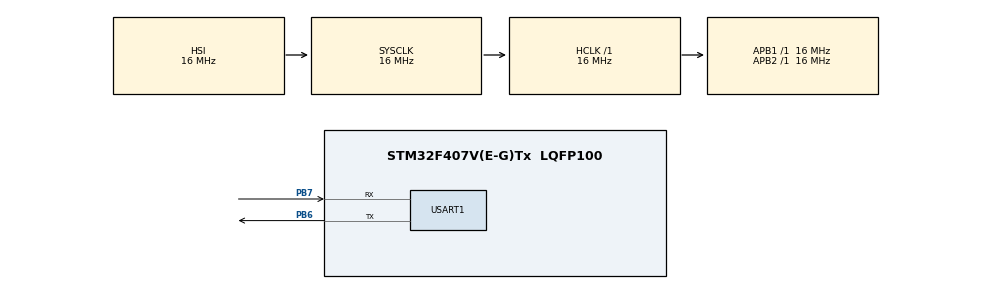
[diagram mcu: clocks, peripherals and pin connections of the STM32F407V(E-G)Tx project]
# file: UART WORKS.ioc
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Mcu.Family=STM32F4
RCC.CortexFreq_Value=16000000
Dma.USART1_RX.0.PeriphDataAlignment=DMA_PDATAALIGN_BYTE
ProjectManager.StackSize=0x400
ProjectManager.TargetToolchain=STM32CubeIDE
Dma.USART1_RX.0.Direction=DMA_PERIPH_TO_MEMORY
PB6.Signal=USART1_TX
PB6.Mode=Asynchronous
RCC.LSE_VALUE=32768
RCC.AHBFreq_Value=16000000
Dma.USART1_RX.0.PeriphInc=DMA_PINC_DISABLE
Dma.USART1_RX.0.Priority=DMA_PRIORITY_LOW
RCC.HSE_VALUE=25000000
board=custom
RCC.VCOOutputFreq_Value=192000000
RCC.APB2Freq_Value=16000000
Dma.USART1_RX.0.MemDataAlignment=DMA_MDATAALIGN_BYTE
PB7.Signal=USART1_RX
Dma.USART1_RX.0.MemInc=DMA_MINC_ENABLE
Mcu.Name=STM32F407V(E-G)Tx
RCC.SYSCLKFreq_VALUE=16000000
Mcu.Package=LQFP100
USART1.VirtualMode=VM_ASYNC
PB7.Mode=Asynchronous
ProjectManager.HeapSize=0x200
RCC.HSI_VALUE=16000000
NVIC.PriorityGroup=NVIC_PRIORITYGROUP_4
Dma.USART1_RX.0.FIFOMode=DMA_FIFOMODE_DISABLE
NVIC.DMA2_Stream2_IRQn=true\:0\:0\:false\:false\:true\:false\:true
Dma.USART1_RX.0.Mode=DMA_CIRCULAR
NVIC.USART1_IRQn=true\:0\:0\:false\:false\:true\:true\:true
Dma.Request0=USART1_RX
RCC.APB1Freq_Value=16000000
Dma.USART1_RX.0.Instance=DMA2_Stream2

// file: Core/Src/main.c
/* USER CODE BEGIN Header */
/**
  ******************************************************************************
  * @file           : main.c
  * @brief          : Main program body
  ******************************************************************************
  * @attention
  *
  * <h2><center>&copy; Copyright (c) 2021 STMicroelectronics.
  * All rights reserved.</center></h2>
  *
  * This software component is licensed by ST under BSD 3-Clause license,
  * the "License"; You may not use this file except in compliance with the
  * License. You may obtain a copy of the License at:
  *                        opensource.org/licenses/BSD-3-Clause
  *
  ******************************************************************************
  */
/* USER CODE END Header */
#include "main.h"

UART_HandleTypeDef huart1;
DMA_HandleTypeDef hdma_usart1_rx;

void SystemClock_Config(void);
static void MX_GPIO_Init(void);
static void MX_DMA_Init(void);
static void MX_USART1_UART_Init(void);

/* USER CODE BEGIN 0 */
uint8_t FirstTxData[26]= "w axis0.requested_state 3\n";
uint8_t myTxData[22]= "r axis0.current_state\n";
uint8_t myTxData1[15]= "r vbus_voltage\n";
uint8_t myRxData[1] = "0";
uint8_t in_buf[16]="0";
uint8_t n_inbuf=0;
/* USER CODE END 0 */

int main(void)
{

  /* MCU Configuration--------------------------------------------------------*/

  /* Reset of all peripherals, Initializes the Flash interface and the Systick. */
  HAL_Init();

  /* Configure the system clock */
  SystemClock_Config();

  /* Initialize all configured peripherals */
  MX_GPIO_Init();
  MX_DMA_Init();
  MX_USART1_UART_Init();
  /* USER CODE BEGIN 2 */
  HAL_UART_Receive_DMA(&huart1, myRxData, 1);
  //HAL_UART_Transmit(&huart1, FirstTxData, 26, 20);
  HAL_Delay(200);
  /* USER CODE END 2 */

  /* Infinite loop */
  while (1)
  {

    /* USER CODE BEGIN 3 */
	  HAL_UART_Transmit(&huart1, myTxData, 22, 20);
	  HAL_Delay(1000);
	  HAL_UART_Transmit(&huart1, myTxData1, 15, 20);

	  HAL_Delay(1000);
  }
  /* USER CODE END 3 */
}

void SystemClock_Config(void)
{
  RCC_OscInitTypeDef RCC_OscInitStruct = {0};
  RCC_ClkInitTypeDef RCC_ClkInitStruct = {0};

  /** Configure the main internal regulator output voltage
  */
  __HAL_RCC_PWR_CLK_ENABLE();
  __HAL_PWR_VOLTAGESCALING_CONFIG(PWR_REGULATOR_VOLTAGE_SCALE1);
  /** Initializes the RCC Oscillators according to the specified parameters
  * in the RCC_OscInitTypeDef structure.
  */
  RCC_OscInitStruct.OscillatorType = RCC_OSCILLATORTYPE_HSI;
  RCC_OscInitStruct.HSIState = RCC_HSI_ON;
  RCC_OscInitStruct.HSICalibrationValue = RCC_HSICALIBRATION_DEFAULT;
  RCC_OscInitStruct.PLL.PLLState = RCC_PLL_NONE;
  if (HAL_RCC_OscConfig(&RCC_OscInitStruct) != HAL_OK)
  {
    Error_Handler();
  }
  /** Initializes the CPU, AHB and APB buses clocks
  */
  RCC_ClkInitStruct.ClockType = RCC_CLOCKTYPE_HCLK|RCC_CLOCKTYPE_SYSCLK
                              |RCC_CLOCKTYPE_PCLK1|RCC_CLOCKTYPE_PCLK2;
  RCC_ClkInitStruct.SYSCLKSource = RCC_SYSCLKSOURCE_HSI;
  RCC_ClkInitStruct.AHBCLKDivider = RCC_SYSCLK_DIV1;
  RCC_ClkInitStruct.APB1CLKDivider = RCC_HCLK_DIV1;
  RCC_ClkInitStruct.APB2CLKDivider = RCC_HCLK_DIV1;

  if (HAL_RCC_ClockConfig(&RCC_ClkInitStruct, FLASH_LATENCY_0) != HAL_OK)
  {
    Error_Handler();
  }
}

static void MX_USART1_UART_Init(void)
{

  huart1.Instance = USART1;
  huart1.Init.BaudRate = 115200;
  huart1.Init.WordLength = UART_WORDLENGTH_8B;
  huart1.Init.StopBits = UART_STOPBITS_1;
  huart1.Init.Parity = UART_PARITY_NONE;
  huart1.Init.Mode = UART_MODE_TX_RX;
  huart1.Init.HwFlowCtl = UART_HWCONTROL_NONE;
  huart1.Init.OverSampling = UART_OVERSAMPLING_16;
  if (HAL_UART_Init(&huart1) != HAL_OK)
  {
    Error_Handler();
  }

}

static void MX_DMA_Init(void)
{

  /* DMA controller clock enable */
  __HAL_RCC_DMA2_CLK_ENABLE();

  /* DMA interrupt init */
  /* DMA2_Stream2_IRQn interrupt configuration */
  HAL_NVIC_SetPriority(DMA2_Stream2_IRQn, 0, 0);
  HAL_NVIC_EnableIRQ(DMA2_Stream2_IRQn);

}

static void MX_GPIO_Init(void)
{

  /* GPIO Ports Clock Enable */
  __HAL_RCC_GPIOB_CLK_ENABLE();

}

/* USER CODE BEGIN 4 */
void HAL_UART_RxCpltCallback(UART_HandleTypeDef *huart)
{
  /* Prevent unused argument(s) compilation warning */
  UNUSED(huart);
  /* NOTE: This function should not be modified, when the callback is needed,
           the HAL_UART_RxCpltCallback could be implemented in the user file
   */

  in_buf[n_inbuf++]=myRxData[0];
  	  if (myRxData[0]=='\n')
  	  {
  		  uint8_t test=0;
  		   test= myRxData;
  		   int exuji;
  		   exuji=test;
  		   for (int i=0;i<n_inbuf ;i++)
  		   {
  			   in_buf[i]=0;
  		   }
  		   n_inbuf=0;
  	  }
}
/* USER CODE END 4 */

void Error_Handler(void)
{
  __disable_irq();
  while (1)
  {
  }
}

/************************ (C) COPYRIGHT STMicroelectronics *****END OF FILE****/
